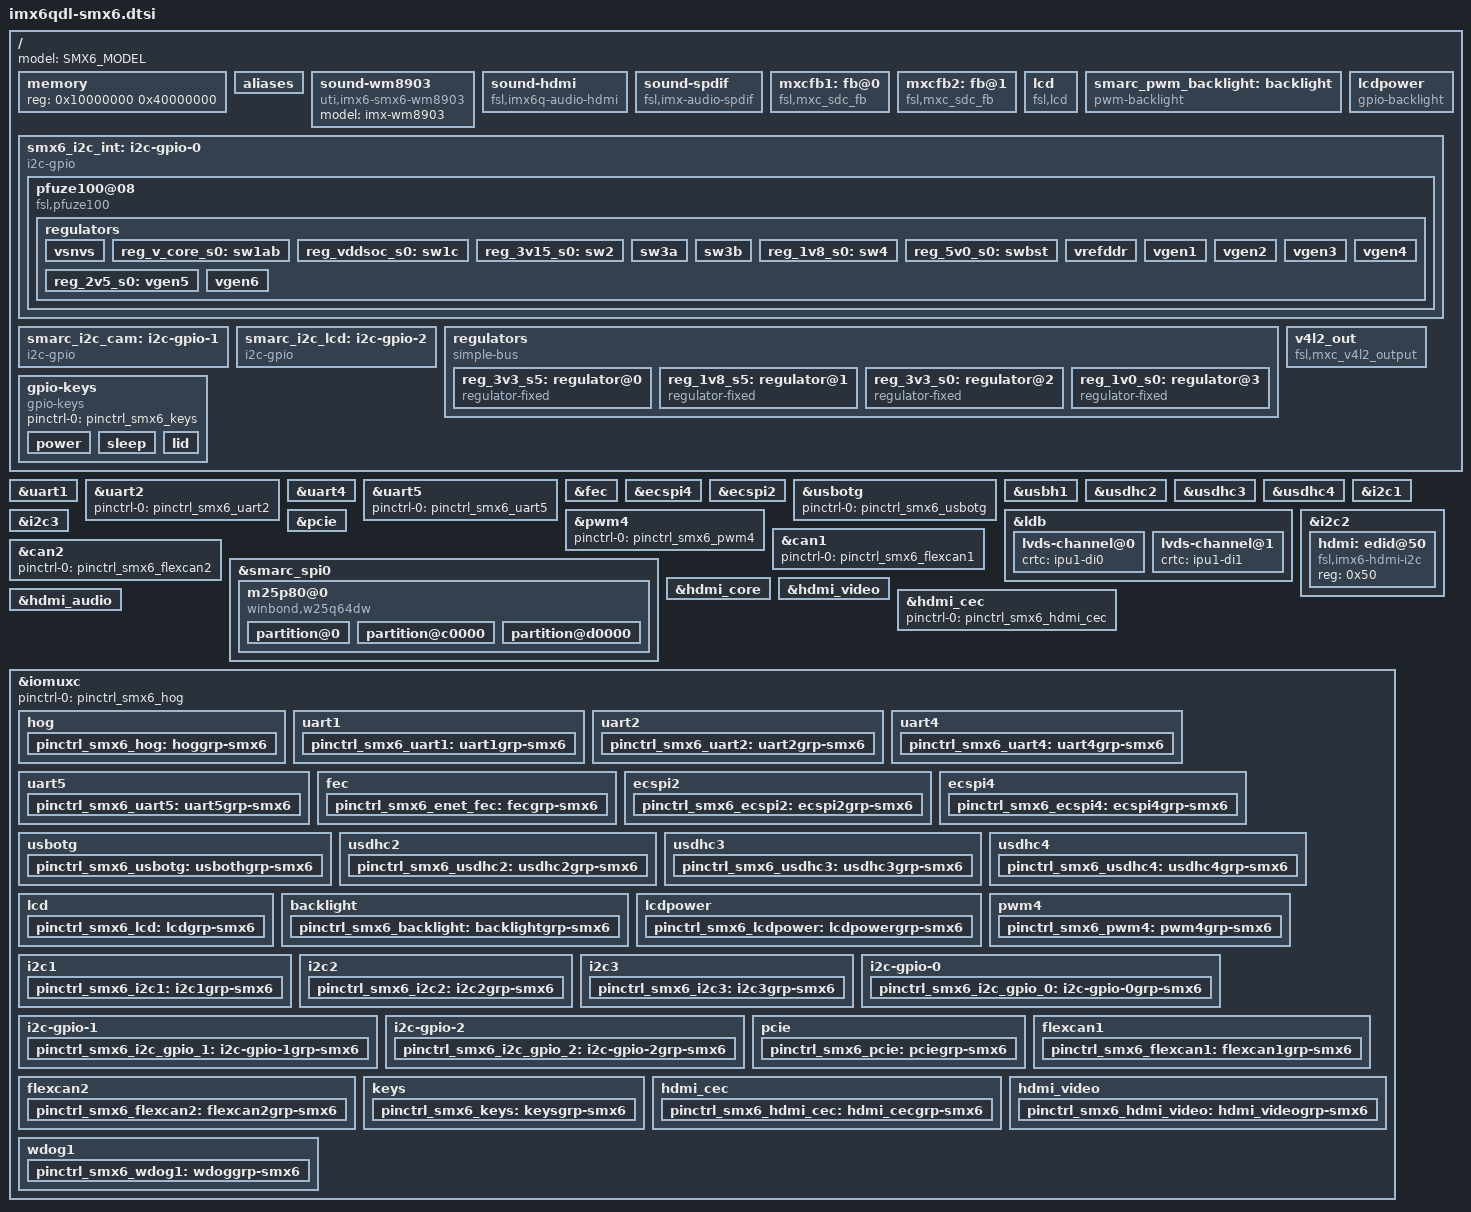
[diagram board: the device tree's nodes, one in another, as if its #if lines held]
/*
 * The code contained herein is licensed under the GNU General Public
 * License. You may obtain a copy of the GNU General Public License
 * Version 2 or later at the following locations:
 *
 * http://www.opensource.org/licenses/gpl-license.html
 * http://www.gnu.org/copyleft/gpl.html
 */

#if !defined(SMX6_CPU_IMX6Q) && !defined(SMX6_CPU_IMX6DL)
#error Please define CPU type
#endif
#if defined(SMX6_CPU_IMX6Q) && defined(SMX6_CPU_IMX6DL)
#error Please define single CPU type
#endif

#if !defined(SMX6_PANEL_LCD) && !defined(SMX6_PANEL_LVDS)
#error Please define panel interface type
#endif
#if defined(SMX6_PANEL_LCD) && defined(SMX6_PANEL_LVDS)
#error Please define single panel interface type
#endif

#ifdef SMX6_CPU_IMX6Q
#include "imx6q.dtsi"
#define SMX6_COMPATIBLE "kontron,imx6q-smx6", "fsl,imx6q"
#endif
#ifdef SMX6_CPU_IMX6DL
#define SMX6_COMPATIBLE "kontron,imx6dl-smx6", "fsl,imx6dl"
#include "imx6dl.dtsi"
#endif

#ifndef SMX6_MODEL
#define SMX6_MODEL "Kontron SMARC-sAMX6i module"
#endif

/ {
        model = SMX6_MODEL;
        compatible = SMX6_COMPATIBLE;

        memory {
                reg = <0x10000000 0x40000000>;
        };

        aliases {
                mxcfb0 = &mxcfb1;
                mxcfb1 = &mxcfb2;
                spi0 = &ecspi4;
                spi1 = &ecspi2;
        };

		sound-wm8903 {
				compatible = "uti,imx6-smx6-wm8903",
							 "uti,imx-audio-wm8903";
				model = "imx-wm8903";
		};

        sound-hdmi {
                compatible = "fsl,imx6q-audio-hdmi",
                             "fsl,imx-audio-hdmi";
                model = "imx-audio-hdmi";
                hdmi-controller = <&hdmi_audio>;
        };

		sound-spdif {
				compatible = "fsl,imx-audio-spdif",
							 "fsl,imx-smx6-spdif";
				model = "imx-spdif";
				spdif-controller = <&spdif>;
				spdif-out;
				spdof-in;
		};

        mxcfb1: fb@0 {
                compatible = "fsl,mxc_sdc_fb";
#ifdef SMX6_PANEL_LCD
                disp_dev = "lcd";
#endif
#ifdef SMX6_PANEL_LVDS
                disp_dev = "ldb";
#endif
                interface_pix_fmt = "RGB24";
                mode_str = "1280x800M@60";
                default_bpp = <32>;
                int_clk = <0>;
                late_init = <0>;
                status = "okay";
        };

        mxcfb2: fb@1 {
                compatible = "fsl,mxc_sdc_fb";
                disp_dev = "hdmi";
                interface_pix_fmt = "RGB24";
                mode_str ="1920x1080M@60";
                default_bpp = <24>;
                int_clk = <0>;
                late_init = <0>;
                status = "okay";
        };

#ifdef SMX6_PANEL_LCD
        lcd {
                compatible = "fsl,lcd";
                pinctrl-names = "default";
                pinctrl-0 = <&pinctrl_smx6_lcd>;
                ipu_id = <0>;
                disp_id = <0>;
                default_ifmt = "RGB24";
                status = "okay";
        };
#endif

        smarc_pwm_backlight: backlight {
                compatible = "pwm-backlight";
                pinctrl-names = "default";
                pinctrl-0 = <&pinctrl_smx6_backlight>;
                pwms = <&pwm4 0 5000000>;
                brightness-levels = <
                        0  1  2  3  4  5  6  7  8  9
                        10 11 12 13 14 15 16 17 18 19
                        20 21 22 23 24 25 26 27 28 29
                        30 31 32 33 34 35 36 37 38 39
                        40 41 42 43 44 45 46 47 48 49
                        50 51 52 53 54 55 56 57 58 59
                        60 61 62 63 64 65 66 67 68 69
                        70 71 72 73 74 75 76 77 78 79
                        80 81 82 83 84 85 86 87 88 89
                        90 91 92 93 94 95 96 97 98 99
                        100
                >;
                default-brightness-level = <80>;
                enable-gpios = <&gpio1 16 GPIO_ACTIVE_HIGH>;
                fb = <&mxcfb1>;
        };

        lcdpower {
                compatible = "gpio-backlight";
                pinctrl-names = "default";
                pinctrl-0 = <&pinctrl_smx6_lcdpower>;
                gpios = <&gpio1 17 GPIO_ACTIVE_HIGH>;
                default-on;
                fb = <&mxcfb1>;
        };

        smx6_i2c_int: i2c-gpio-0 {
                compatible = "i2c-gpio";
                pinctrl-names = "default";
                pinctrl-0 = <&pinctrl_smx6_i2c_gpio_0>;
                gpios =
                        <&gpio1 28 0>, /* sda */
                        <&gpio1 30 0>; /* scl */
                #address-cells = <1>;
                #size-cells = <0>;
                i2c-gpio,delay-us = <2>;
        };

        smarc_i2c_cam: i2c-gpio-1 {
                compatible = "i2c-gpio";
                pinctrl-names = "default";
                pinctrl-0 = <&pinctrl_smx6_i2c_gpio_1>;
                gpios =
                        <&gpio4 10 0>, /* sda */
                        <&gpio1 6 0>;  /* scl */
                #address-cells = <1>;
                #size-cells = <0>;
                i2c-gpio,delay-us = <2>;
        };

        smarc_i2c_lcd: i2c-gpio-2 {
                compatible = "i2c-gpio";
                pinctrl-names = "default";
                pinctrl-0 = <&pinctrl_smx6_i2c_gpio_2>;
                gpios =
                        <&gpio1 21 0>, /* sda */
                        <&gpio1 19 0>; /* scl */
                #address-cells = <1>;
                #size-cells = <0>;
                i2c-gpio,delay-us = <2>;
        };

        regulators {
                compatible = "simple-bus";
                #address-cells = <1>;
                #size-cells = <0>;

                reg_3v3_s5: regulator@0 {
                        compatible = "regulator-fixed";
                        reg = <0>;
                        regulator-name = "V_3V3_S5";
                        regulator-min-microvolt = <3300000>;
                        regulator-max-microvolt = <3300000>;
                        regulator-boot-on;
                        regulator-always-on;
                };

                reg_1v8_s5: regulator@1 {
                        compatible = "regulator-fixed";
                        reg = <1>;
                        regulator-name = "V_1V8_S5";
                        regulator-min-microvolt = <1800000>;
                        regulator-max-microvolt = <1800000>;
                        regulator-boot-on;
                        regulator-always-on;
                };

                reg_3v3_s0: regulator@2 {
                        compatible = "regulator-fixed";
                        reg = <2>;
                        regulator-name = "V_3V3_S0";
                        regulator-min-microvolt = <3300000>;
                        regulator-max-microvolt = <3300000>;
                        regulator-boot-on;
                        regulator-always-on;
                };

                reg_1v0_s0: regulator@3 {
                        compatible = "regulator-fixed";
                        reg = <3>;
                        regulator-name = "V_1V0_S0";
                        regulator-min-microvolt = <1000000>;
                        regulator-max-microvolt = <1000000>;
                        regulator-boot-on;
                        regulator-always-on;
                };
        };

        gpio-keys {
                compatible = "gpio-keys";
                pinctrl-names = "default";
                pinctrl-0 = <&pinctrl_smx6_keys>;
                power {
                        label = "Power";
                        gpios = <&gpio6 16 1>;
                        linux,code = <116>; /* KEY_POWER */
                        gpio-key,wakeup;
                        debounce-interval = <1>;
                };

                sleep {
                        label = "Sleep";
                        gpios = <&gpio6 17 1>;
                        linux,code = <142>; /* KEY_SLEEP */
                        gpio-key,wakeup;
                        debounce-interval = <1>;
                };

                lid {
                        label = "Lid";
                        gpios = <&gpio5 0 1>;
                        linux,input-type = <5>; /* EV_SW */
                        linux,code = <0>; /* SW_LID */
                        gpio-key,wakeup;
                        debounce-interval = <1>;
                };
        };

        v4l2_out {
                compatible = "fsl,mxc_v4l2_output";
                status = "okay";
        };
};

#define smarc_ser0 uart1
&uart1 {
        pinctrl-names = "default";
        pinctrl-0 = <&pinctrl_smx6_uart1>;
        fsl,uart-has-rtscts;
};

#define smarc_ser1 uart2
&uart2 {
        pinctrl-names = "default";
        pinctrl-0 = <&pinctrl_smx6_uart2>;
};

#define smarc_ser2 uart4
&uart4 {
        pinctrl-names = "default";
        pinctrl-0 = <&pinctrl_smx6_uart4>;
        fsl,uart-has-rtscts;
};

#define smarc_ser3 uart5
&uart5 {
        pinctrl-names = "default";
        pinctrl-0 = <&pinctrl_smx6_uart5>;
};

&fec {
        pinctrl-names = "default";
        pinctrl-0 = <&pinctrl_smx6_enet_fec>;
        phy-mode = "rgmii";
        status = "okay";
};

#define smarc_spi0 ecspi4
&ecspi4 {
        pinctrl-names = "default";
        pinctrl-0 = <&pinctrl_smx6_ecspi4>;
        fsl,spi-num-chipselects = <3>;
        cs-gpios = <&gpio3 24 0>, <&gpio3 29 0>, <&gpio3 25 0>;
        status = "okay";
};

#define smarc_spi1 ecspi2
&ecspi2 {
        pinctrl-names = "default";
        pinctrl-0 = <&pinctrl_smx6_ecspi2>;
        fsl,spi-num-chipselects = <2>;
        cs-gpios = <&gpio2 26 0>, <&gpio2 27 0>;
        status = "okay";
};

&usbotg {
        pinctrl-names = "default";
        pinctrl-0 = <&pinctrl_smx6_usbotg>;
        /* no 'imx6-usb-charger-detection' since USB_OTG_CHD_B pin is not wired 
*/
        status = "okay";
};

&usbh1 {
        status = "okay";
};

#define smarc_sdmmc usdhc2
&usdhc2 {
        pinctrl-names = "default";
        pinctrl-0 = <&pinctrl_smx6_usdhc2>;
        bus-width = <8>;
        cd-gpios = <&gpio1 4 GPIO_ACTIVE_LOW>;        /* per schematics, always constant? */
};

#define smarc_sdio usdhc3
&usdhc3 {
        pinctrl-names = "default";
        pinctrl-0 = <&pinctrl_smx6_usdhc3>;
        bus-width = <4>;
        cd-gpios = <&gpio6 14 GPIO_ACTIVE_LOW>;
        wp-gpios = <&gpio1 26 GPIO_ACTIVE_HIGH>;
        no-1-8-v;
	status = "okay";
};
#define SMARC_SDIO_PWR_EN_GPIO <&gpio1 29 GPIO_ACTIVE_HIGH>

#ifndef SMX6_HIDE_EMMC
&usdhc4 {
        pinctrl-names = "default";
        pinctrl-0 = <&pinctrl_smx6_usdhc4>;
        bus-width = <8>;
        no-1-8-v;
        non-removable;
        status = "okay";
};
#endif

#ifdef SMX6_PANEL_LVDS
&ldb {
        mode = "sin0";
        ipu_id = <0>;
        disp_id = <0>;
        sec_ipu_id = <0>;
        sec_disp_id = <0>;
        ext_ref = <1>;
        status = "okay";

	lvds-channel@0 {
		crtc = "ipu1-di0";
	};

	lvds-channel@1 {
		crtc = "ipu1-di1";
	};
};
#endif

&pwm4 {
        pinctrl-names = "default";
        pinctrl-0 = <&pinctrl_smx6_pwm4>;
        status = "okay";
};

#define smarc_i2c_gp i2c1
&i2c1 {
        clock-frequency = <100000>;
        pinctrl-names = "default";
        pinctrl-0 = <&pinctrl_smx6_i2c1>;
        status = "okay";
};

#ifndef SMX6_HDCP
#define smarc_i2c_hdmi i2c2
&i2c2 {
        clock-frequency = <100000>;
        pinctrl-names = "default";
        pinctrl-0 = <&pinctrl_smx6_i2c2>;
        status = "okay";

        hdmi: edid@50 {
                compatible = "fsl,imx6-hdmi-i2c";
                reg = <0x50>;
        };
};
#endif

#define smarc_i2c_pm i2c3
&i2c3 {
        clock-frequency = <100000>;
        pinctrl-names = "default";
        pinctrl-0 = <&pinctrl_smx6_i2c3>;
        status = "okay";
};

&pcie {
        wake-up-gpio = <&gpio6 18 0>;
#ifdef SMX6_PCIE_SWITCH
        reset-gpio = <&gpio2 0 GPIO_ACTIVE_LOW>,
                     <&gpio3 13 GPIO_ACTIVE_LOW>,
                     <&gpio3 14 GPIO_ACTIVE_LOW>,
                     <&gpio3 15 GPIO_ACTIVE_LOW>;
        no-gen2;
#else
        reset-gpio = <&gpio3 13 GPIO_ACTIVE_LOW>;
#endif
        pinctrl-names = "default";
        pinctrl-0 = <&pinctrl_smx6_pcie>;
        status = "okay";
};

#ifdef SMX6_CPU_IMX6Q
#define smarc_sata sata
#endif

#define smarc_can0 can1
&can1 {
        pinctrl-names = "default";
        pinctrl-0 = <&pinctrl_smx6_flexcan1>;
};

#define smarc_can1 can2
&can2 {
        pinctrl-names = "default";
        pinctrl-0 = <&pinctrl_smx6_flexcan2>;
};


&smx6_i2c_int {
        pfuze100@08 {
                compatible = "fsl,pfuze100";
                reg = <0x08>;

                /* Looks unused by pfuze100 driver */
                interrupt-parent = <&gpio7>;
                interrupts = <13 8>;    /* 8 = level, active low */

                regulators {
                        vsnvs {
                                regulator-min-microvolt = <1000000>;
                                regulator-max-microvolt = <3000000>;
                                regulator-boot-on;
                                regulator-always-on;
                        };

                        reg_v_core_s0: sw1ab {
                                regulator-name = "V_CORE_S0";
                                regulator-min-microvolt = <300000>;
                                regulator-max-microvolt = <1875000>;
                                regulator-boot-on;
                                regulator-always-on;
                        };

                        reg_vddsoc_s0: sw1c {
                                regulator-name = "V_VDDSOC_S0";
                                regulator-min-microvolt = <300000>;
                                regulator-max-microvolt = <1875000>;
                                regulator-boot-on;
                                regulator-always-on;
                        };

                        reg_3v15_s0: sw2 {
                                regulator-name = "V_3V15_S0";
                                regulator-min-microvolt = <800000>;
                                regulator-max-microvolt = <3300000>;
                                regulator-boot-on;
                                regulator-always-on;
                        };

                        /* sw3a/b is used in dual mode, but driver does not
                         * support it?  anyway, no need to control DDR
                         * power - so just leaving dummy entries for sw3a
                         * and sw3b for now */

                        sw3a {
                                regulator-min-microvolt = <400000>;
                                regulator-max-microvolt = <1975000>;
                                regulator-boot-on;
                                regulator-always-on;
                        };

                        sw3b {
                                regulator-min-microvolt = <400000>;
                                regulator-max-microvolt = <1975000>;
                                regulator-boot-on;
                                regulator-always-on;
                        };

                        reg_1v8_s0: sw4 {
                                regulator-name = "V_1V8_S0";
                                regulator-min-microvolt = <800000>;
                                regulator-max-microvolt = <3300000>;
                                regulator-boot-on;
                                regulator-always-on;
                        };

                        reg_5v0_s0: swbst {
                                regulator-name = "V_5V0_S0";
                                regulator-min-microvolt = <5000000>;
                                regulator-max-microvolt = <5150000>;
                        };

                        vrefddr {
                                regulator-boot-on;
                                regulator-always-on;
                        };

                        /* Per schematics, of all VGEN's, only VGEN5 has some
                           usage ... but even that - over DNI resistor */

                        vgen1 {
                                regulator-min-microvolt = <800000>;
                                regulator-max-microvolt = <1550000>;
                        };

                        vgen2 {
                                regulator-min-microvolt = <800000>;
                                regulator-max-microvolt = <1550000>;
                        };

                        vgen3 {
                                regulator-min-microvolt = <1800000>;
                                regulator-max-microvolt = <3300000>;
                        };

                        vgen4 {
                                regulator-min-microvolt = <1800000>;
                                regulator-max-microvolt = <3300000>;
                        };

                        reg_2v5_s0: vgen5 {
                                regulator-name = "V_2V5_S0";
                                regulator-min-microvolt = <1800000>;
                                regulator-max-microvolt = <3300000>;
                        };

                        vgen6 {
                                regulator-min-microvolt = <1800000>;
                                regulator-max-microvolt = <3300000>;
                        };
                };
        };
};

#ifndef SMX6_HIDE_SPI_FLASH
&smarc_spi0 {
        m25p80@0 {
                #address-cells = <1>;
                #size-cells = <1>;
                compatible = "winbond,w25q64dw";
                spi-max-frequency = <20000000>;
                reg = <0>;

                partition@0 {
                        label = "bootloader";
                        reg = <0x000000 0x0c0000>;
                        read-only;
                };
                partition@c0000 {
                        label = "environment";
                        reg = <0x0c0000 0x010000>;
                };
                partition@d0000 {
                        label = "user";
                        reg = <0x0d0000 0x730000>;
                };
        };
};
#endif

#ifdef SMX6_CPU_IMX6Q
#define smarc_sata sata
#endif

&hdmi_core {
#ifdef SMX6_CPU_IMX6Q
        ipu_id = <1>;
        disp_id = <0>;
#endif
#ifdef SMX6_CPU_IMX6DL
        ipu_id = <0>;
        disp_id = <1>;
#endif
        status = "okay";
};

&hdmi_video {
#ifdef SMX6_HDCP
        pinctrl-names = "default";
        pinctrl-0 = <&pinctrl_smx6_hdmi_video>;
        fsl,hdcp;
#endif
        status = "okay";
};

&hdmi_audio {
        status = "okay";
};

&hdmi_cec {
        pinctrl-names = "default";
        pinctrl-0 = <&pinctrl_smx6_hdmi_cec>;
        status = "okay";
};

/* comment out WGOR_B pin configuration for now - it causes board reboots */
/*&wdog1 {
        pinctrl-names = "default";
        pinctrl-0 = <&pinctrl_smx6_wdog1>;
};*/

&iomuxc {
        pinctrl-names = "default";
        pinctrl-0 = <&pinctrl_smx6_hog>;

        hog {
                pinctrl_smx6_hog: hoggrp-smx6 {
                        fsl,pins = <

                                /* SMARC GPIO lines - enable SION bit */
                                MX6QDL_PAD_EIM_DA0__GPIO3_IO00 0x4000b0b1
                                MX6QDL_PAD_EIM_DA1__GPIO3_IO01 0x4000b0b1
                                MX6QDL_PAD_EIM_DA2__GPIO3_IO02 0x4000b0b1
                                MX6QDL_PAD_EIM_DA3__GPIO3_IO03 0x4000b0b1
                                MX6QDL_PAD_EIM_DA4__GPIO3_IO04 0x4000b0b1
                                MX6QDL_PAD_EIM_DA5__GPIO3_IO05 0x4000b0b1
                                MX6QDL_PAD_EIM_DA6__GPIO3_IO06 0x4000b0b1
                                MX6QDL_PAD_EIM_DA7__GPIO3_IO07 0x4000b0b1
                                MX6QDL_PAD_EIM_DA8__GPIO3_IO08 0x4000b0b1
                                MX6QDL_PAD_EIM_DA9__GPIO3_IO09 0x4000b0b1
                                MX6QDL_PAD_EIM_DA10__GPIO3_IO10 0x4000b0b1
                                MX6QDL_PAD_EIM_DA11__GPIO3_IO11 0x4000b0b1
                        >;
                };
        };

        uart1 {
                pinctrl_smx6_uart1: uart1grp-smx6 {
                        fsl,pins = <
                                MX6QDL_PAD_CSI0_DAT11__UART1_RX_DATA 0x1b0b1
                                MX6QDL_PAD_CSI0_DAT10__UART1_TX_DATA 0x1b0b1
                                MX6QDL_PAD_EIM_D20__UART1_RTS_B 0x1b0b1
                                MX6QDL_PAD_EIM_D19__UART1_CTS_B 0x1b0b1
                        >;
                };
        };

        uart2 {
                pinctrl_smx6_uart2: uart2grp-smx6 {
                        fsl,pins = <
                                MX6QDL_PAD_EIM_D27__UART2_RX_DATA 0x1b0b1
                                MX6QDL_PAD_EIM_D26__UART2_TX_DATA 0x1b0b1
                        >;
                };
        };

        uart4 {
                pinctrl_smx6_uart4: uart4grp-smx6 {
                        fsl,pins = <
                                MX6QDL_PAD_CSI0_DAT13__UART4_RX_DATA 0x1b0b1
                                MX6QDL_PAD_CSI0_DAT12__UART4_TX_DATA 0x1b0b1
                                MX6QDL_PAD_CSI0_DAT16__UART4_RTS_B 0x1b0b1
                                MX6QDL_PAD_CSI0_DAT17__UART4_CTS_B 0x1b0b1
                        >;
                };
        };
        
        uart5 {
                pinctrl_smx6_uart5: uart5grp-smx6 {
                        fsl,pins = <
                                MX6QDL_PAD_CSI0_DAT15__UART5_RX_DATA 0x1b0b1
                                MX6QDL_PAD_CSI0_DAT14__UART5_TX_DATA 0x1b0b1
                        >;
                };
        };

        fec {
                pinctrl_smx6_enet_fec: fecgrp-smx6 {
                        fsl,pins = <
                                MX6QDL_PAD_ENET_MDIO__ENET_MDIO       0x1b0b0
                                MX6QDL_PAD_ENET_MDC__ENET_MDC         0x1b0b0
                                MX6QDL_PAD_RGMII_TXC__RGMII_TXC       0x1b0b0
                                MX6QDL_PAD_RGMII_TD0__RGMII_TD0       0x1b0b0
                                MX6QDL_PAD_RGMII_TD1__RGMII_TD1       0x1b0b0
                                MX6QDL_PAD_RGMII_TD2__RGMII_TD2       0x1b0b0
                                MX6QDL_PAD_RGMII_TD3__RGMII_TD3       0x1b0b0
                                MX6QDL_PAD_RGMII_TX_CTL__RGMII_TX_CTL 0x1b0b0
                                MX6QDL_PAD_ENET_REF_CLK__ENET_TX_CLK  0x1b0b0
                                MX6QDL_PAD_RGMII_RXC__RGMII_RXC       0x1b0b0
                                MX6QDL_PAD_RGMII_RD0__RGMII_RD0       0x1b0b0
                                MX6QDL_PAD_RGMII_RD1__RGMII_RD1       0x1b0b0
                                MX6QDL_PAD_RGMII_RD2__RGMII_RD2       0x1b0b0
                                MX6QDL_PAD_RGMII_RD3__RGMII_RD3       0x1b0b0
                                MX6QDL_PAD_RGMII_RX_CTL__RGMII_RX_CTL 0x1b0b0
                        >;
                };
        };

        ecspi2 {
                pinctrl_smx6_ecspi2: ecspi2grp-smx6 {
                        fsl,pins = <
                                MX6QDL_PAD_EIM_CS0__ECSPI2_SCLK 0x80000000
                                MX6QDL_PAD_EIM_CS1__ECSPI2_MOSI 0x80000000
                                MX6QDL_PAD_EIM_OE__ECSPI2_MISO 0x80000000

                                MX6QDL_PAD_EIM_RW__GPIO2_IO26 0x80000000
                                MX6QDL_PAD_EIM_LBA__GPIO2_IO27 0x80000000
                        >;
                };
        };

        ecspi4 {
                pinctrl_smx6_ecspi4: ecspi4grp-smx6 {
                        fsl,pins = <
                                MX6QDL_PAD_EIM_D21__ECSPI4_SCLK 0x80000000
                                MX6QDL_PAD_EIM_D28__ECSPI4_MOSI 0x80000000
                                MX6QDL_PAD_EIM_D22__ECSPI4_MISO 0x80000000

                                /* In hardware, ECSPI4's SS0,SS1,SS3 are wired.
                                   But spi-imx driver support only continuous
                                   numbering, and only can use GPIOs (and not
                                   ECSPI's hardware SS) for CS. So linux view
                                   of CS numbers differs from hw view, and
                                   pins are configured as GPIOs */

                                /* physical - CS2, in linux - CS0, either internal flash or SMARC CS0 */
                                MX6QDL_PAD_EIM_D24__GPIO3_IO24 0x80000000
                                /* physical - CS0, in linux - CS1, either SMARC CS0 or not-connected */
                                MX6QDL_PAD_EIM_D29__GPIO3_IO29 0x80000000
                                /* physical - CS3, in linux - CS2, SMARC CS1 */
                                MX6QDL_PAD_EIM_D25__GPIO3_IO25 0x80000000
                        >;
                };
        };

        usbotg {
                pinctrl_smx6_usbotg: usbothgrp-smx6 {
                        fsl,pins = <
                                MX6QDL_PAD_GPIO_1__USB_OTG_ID 0x1f8b0
                                /* Comment out power and OC gpio's for now, since these
                                   are not used by driver */
                                // MX6QDL_PAD_CSI0_PIXCLK__GPIO5_IO18 0x80000000        /* USB power */
                                // MX6QDL_PAD_CSI0_DATA_EN__GPIO5_IO20 0x80000000       /* USB OC */
                        >;
                };
        };

        usdhc2 {
                pinctrl_smx6_usdhc2: usdhc2grp-smx6 {
                        fsl,pins = <
                                MX6QDL_PAD_SD2_CLK__SD2_CLK 0x17059
                                MX6QDL_PAD_SD2_CMD__SD2_CMD 0x17059
                                MX6QDL_PAD_SD2_DAT0__SD2_DATA0 0x17059
                                MX6QDL_PAD_SD2_DAT1__SD2_DATA1 0x17059
                                MX6QDL_PAD_SD2_DAT2__SD2_DATA2 0x17059
                                MX6QDL_PAD_SD2_DAT3__SD2_DATA3 0x17059
                                MX6QDL_PAD_NANDF_D4__SD2_DATA4 0x17059
                                MX6QDL_PAD_NANDF_D5__SD2_DATA5 0x17059
                                MX6QDL_PAD_NANDF_D6__SD2_DATA6 0x17059
                                MX6QDL_PAD_NANDF_D7__SD2_DATA7 0x17059
                                MX6QDL_PAD_GPIO_4__GPIO1_IO04 0x80000000 /* CD */
                        >;
                };
        };

        usdhc3 {
                pinctrl_smx6_usdhc3: usdhc3grp-smx6 {
                        fsl,pins = <
                                MX6QDL_PAD_SD3_CLK__SD3_CLK 0x17059
                                MX6QDL_PAD_SD3_CMD__SD3_CMD 0x17059
                                MX6QDL_PAD_SD3_DAT0__SD3_DATA0 0x17059
                                MX6QDL_PAD_SD3_DAT1__SD3_DATA1 0x17059
                                MX6QDL_PAD_SD3_DAT2__SD3_DATA2 0x17059
                                MX6QDL_PAD_SD3_DAT3__SD3_DATA3 0x17059
                                MX6QDL_PAD_NANDF_CS1__GPIO6_IO14 0x80000000 /* CD */
                                MX6QDL_PAD_ENET_RXD1__GPIO1_IO26 0x80000000 /* WP */
                                /* FIXME: should this be moved to regulator's
                                          group? */
                                MX6QDL_PAD_ENET_TXD1__GPIO1_IO29 0x80000000 /* PWR_EN */
                        >;
                };
        };

        usdhc4 {
                pinctrl_smx6_usdhc4: usdhc4grp-smx6 {
                        fsl,pins = <
                                MX6QDL_PAD_SD4_CLK__SD4_CLK 0x17059
                                MX6QDL_PAD_SD4_CMD__SD4_CMD 0x17059
                                MX6QDL_PAD_SD4_DAT0__SD4_DATA0 0x17059
                                MX6QDL_PAD_SD4_DAT1__SD4_DATA1 0x17059
                                MX6QDL_PAD_SD4_DAT2__SD4_DATA2 0x17059
                                MX6QDL_PAD_SD4_DAT3__SD4_DATA3 0x17059
                                MX6QDL_PAD_SD4_DAT4__SD4_DATA4 0x17059
                                MX6QDL_PAD_SD4_DAT5__SD4_DATA5 0x17059
                                MX6QDL_PAD_SD4_DAT6__SD4_DATA6 0x17059
                                MX6QDL_PAD_SD4_DAT7__SD4_DATA7 0x17059
                        >;
                };
        };

        lcd {
                pinctrl_smx6_lcd: lcdgrp-smx6 {
                        fsl,pins = <
                                MX6QDL_PAD_DISP0_DAT0__IPU1_DISP0_DATA00 0x100f1
                                MX6QDL_PAD_DISP0_DAT1__IPU1_DISP0_DATA01 0x100f1
                                MX6QDL_PAD_DISP0_DAT2__IPU1_DISP0_DATA02 0x100f1
                                MX6QDL_PAD_DISP0_DAT3__IPU1_DISP0_DATA03 0x100f1
                                MX6QDL_PAD_DISP0_DAT4__IPU1_DISP0_DATA04 0x100f1
                                MX6QDL_PAD_DISP0_DAT5__IPU1_DISP0_DATA05 0x100f1
                                MX6QDL_PAD_DISP0_DAT6__IPU1_DISP0_DATA06 0x100f1
                                MX6QDL_PAD_DISP0_DAT7__IPU1_DISP0_DATA07 0x100f1
                                MX6QDL_PAD_DISP0_DAT8__IPU1_DISP0_DATA08 0x100f1
                                MX6QDL_PAD_DISP0_DAT9__IPU1_DISP0_DATA09 0x100f1
                                MX6QDL_PAD_DISP0_DAT10__IPU1_DISP0_DATA10 0x100f1
                                MX6QDL_PAD_DISP0_DAT11__IPU1_DISP0_DATA11 0x100f1
                                MX6QDL_PAD_DISP0_DAT12__IPU1_DISP0_DATA12 0x100f1
                                MX6QDL_PAD_DISP0_DAT13__IPU1_DISP0_DATA13 0x100f1
                                MX6QDL_PAD_DISP0_DAT14__IPU1_DISP0_DATA14 0x100f1
                                MX6QDL_PAD_DISP0_DAT15__IPU1_DISP0_DATA15 0x100f1
                                MX6QDL_PAD_DISP0_DAT16__IPU1_DISP0_DATA16 0x100f1
                                MX6QDL_PAD_DISP0_DAT17__IPU1_DISP0_DATA17 0x100f1
                                MX6QDL_PAD_DISP0_DAT18__IPU1_DISP0_DATA18 0x100f1
                                MX6QDL_PAD_DISP0_DAT19__IPU1_DISP0_DATA19 0x100f1
                                MX6QDL_PAD_DISP0_DAT20__IPU1_DISP0_DATA20 0x100f1
                                MX6QDL_PAD_DISP0_DAT21__IPU1_DISP0_DATA21 0x100f1
                                MX6QDL_PAD_DISP0_DAT22__IPU1_DISP0_DATA22 0x100f1
                                MX6QDL_PAD_DISP0_DAT23__IPU1_DISP0_DATA23 0x100f1
                                MX6QDL_PAD_DI0_DISP_CLK__IPU1_DI0_DISP_CLK 0x100f1
                                MX6QDL_PAD_DI0_PIN15__IPU1_DI0_PIN15 0x100f1 /* DE */
                                MX6QDL_PAD_DI0_PIN2__IPU1_DI0_PIN02 0x100f1  /* HSYNC */
                                MX6QDL_PAD_DI0_PIN3__IPU1_DI0_PIN03 0x100f1  /* VSYNC */
                        >;
                };
        };

        backlight {
                pinctrl_smx6_backlight: backlightgrp-smx6 {
                        fsl,pins = <
                                MX6QDL_PAD_SD1_DAT0__GPIO1_IO16 0x80000000
                        >;
                };
        };

        lcdpower {
                pinctrl_smx6_lcdpower: lcdpowergrp-smx6 {
                        fsl,pins = <
                                MX6QDL_PAD_SD1_DAT1__GPIO1_IO17 0x80000000
                        >;
                };
        };

        pwm4 {
                pinctrl_smx6_pwm4: pwm4grp-smx6 {
                        fsl,pins = <
                                MX6QDL_PAD_SD1_CMD__PWM4_OUT 0x80000000
                        >;
                };
        };

        i2c1 {
                pinctrl_smx6_i2c1: i2c1grp-smx6 {
                        fsl,pins = <
                                MX6QDL_PAD_CSI0_DAT8__I2C1_SDA 0x4001b8b1
                                MX6QDL_PAD_CSI0_DAT9__I2C1_SCL 0x4001b8b1
                        >;
                };
        };

        i2c2 {
                pinctrl_smx6_i2c2: i2c2grp-smx6 {
                        fsl,pins = <
                                MX6QDL_PAD_KEY_COL3__I2C2_SCL 0x4001b8b1
                                MX6QDL_PAD_KEY_ROW3__I2C2_SDA 0x4001b8b1
                        >;
                };
        };

        i2c3 {
                pinctrl_smx6_i2c3: i2c3grp-smx6 {
                        fsl,pins = <
                                MX6QDL_PAD_GPIO_5__I2C3_SCL  0x4001b8b1
                                MX6QDL_PAD_GPIO_16__I2C3_SDA 0x4001b8b1
                        >;
                };
        };

        i2c-gpio-0 {
                pinctrl_smx6_i2c_gpio_0: i2c-gpio-0grp-smx6 {
                        fsl,pins = <
                                /* SCL GPIO */
                                MX6QDL_PAD_ENET_TXD0__GPIO1_IO30  0x80000000
                                /* SDA GPIO */
                                MX6QDL_PAD_ENET_TX_EN__GPIO1_IO28 0x80000000
                        >;
                };
        };

        i2c-gpio-1 {
                pinctrl_smx6_i2c_gpio_1: i2c-gpio-1grp-smx6 {
                        fsl,pins = <
                                /* SCL GPIO */
                                MX6QDL_PAD_GPIO_6__GPIO1_IO06   0x80000000
                                /* SDA GPIO */
                                MX6QDL_PAD_KEY_COL2__GPIO4_IO10 0x80000000
                        >;
                };
        };

        i2c-gpio-2 {
                pinctrl_smx6_i2c_gpio_2: i2c-gpio-2grp-smx6 {
                        fsl,pins = <
                                /* SCL GPIO */
                                MX6QDL_PAD_SD1_DAT2__GPIO1_IO19 0x80000000
                                /* SDA GPIO */
                                MX6QDL_PAD_SD1_DAT3__GPIO1_IO21 0x80000000
                        >;
                };
        };

        pcie {
                pinctrl_smx6_pcie: pciegrp-smx6 {
                        fsl,pins = <
                                /* RST_PCIE_(SWITCH,A,B,C)# */
                                MX6QDL_PAD_NANDF_D0__GPIO2_IO00 0x80000000
                                MX6QDL_PAD_EIM_DA13__GPIO3_IO13 0x80000000
                                MX6QDL_PAD_EIM_DA14__GPIO3_IO14 0x80000000
                                MX6QDL_PAD_EIM_DA15__GPIO3_IO15 0x80000000
                                /* PCIE_WAKE# */
                                MX6QDL_PAD_SD3_DAT6__GPIO6_IO18 0x80000000
                        >;
                };
        };

        flexcan1 {
                pinctrl_smx6_flexcan1: flexcan1grp-smx6 {
                        fsl,pins = <
                                MX6QDL_PAD_GPIO_7__FLEXCAN1_TX 0x80000000
                                MX6QDL_PAD_GPIO_8__FLEXCAN1_RX 0x80000000
                        >;
                };
        };

        flexcan2 {
                pinctrl_smx6_flexcan2: flexcan2grp-smx6 {
                        fsl,pins = <
                                MX6QDL_PAD_KEY_COL4__FLEXCAN2_TX 0x80000000
                                MX6QDL_PAD_KEY_ROW4__FLEXCAN2_RX 0x80000000
                        >;
                };
        };

        keys {
                pinctrl_smx6_keys: keysgrp-smx6 {
                        fsl,pins = <
                                /* Power Button */
                                MX6QDL_PAD_NANDF_CS3__GPIO6_IO16 0x80000000
                                /* SLEEP# */
                                MX6QDL_PAD_SD3_DAT7__GPIO6_IO17 0x80000000
                                /* LID# */
                                MX6QDL_PAD_EIM_WAIT__GPIO5_IO00 0x80000000
                        >;
                };
        };

        hdmi_cec {
                pinctrl_smx6_hdmi_cec: hdmi_cecgrp-smx6 {
                        fsl,pins = <
                                MX6QDL_PAD_EIM_A25__HDMI_TX_CEC_LINE 0x1f8b0
                        >;
                };
        };

        hdmi_video {
                pinctrl_smx6_hdmi_video: hdmi_videogrp-smx6 {
                        fsl,pins = <
                                MX6QDL_PAD_KEY_COL3__HDMI_TX_DDC_SCL 0x4001b8b1
                                MX6QDL_PAD_KEY_ROW3__HDMI_TX_DDC_SDA 0x4001b8b1
                        >;
                };
        };

        wdog1 {
                pinctrl_smx6_wdog1: wdoggrp-smx6 {
                        fsl,pins = <
                                MX6QDL_PAD_GPIO_9__WDOG1_B 0x80000000
                        >;
                };
        };
};

